# STM32WL31 register map
File version: 1.2
CPU: CM0+ r0p0, little endian, MPU, no FPU, 4 interrupt priority bits
Registers are 32-bit, read-write, reset 0x0 unless marked. A register's access mark holds for its fields unless they carry their own. Offsets are from the block's base; [hi:lo] are bit positions.

## DYNAMIC_REG
Base 0x49000500
0x00 PCKTLEN_CONFIG reset 0x14
  [15:0] PCKTLEN — This bit field has different meanings/usages:
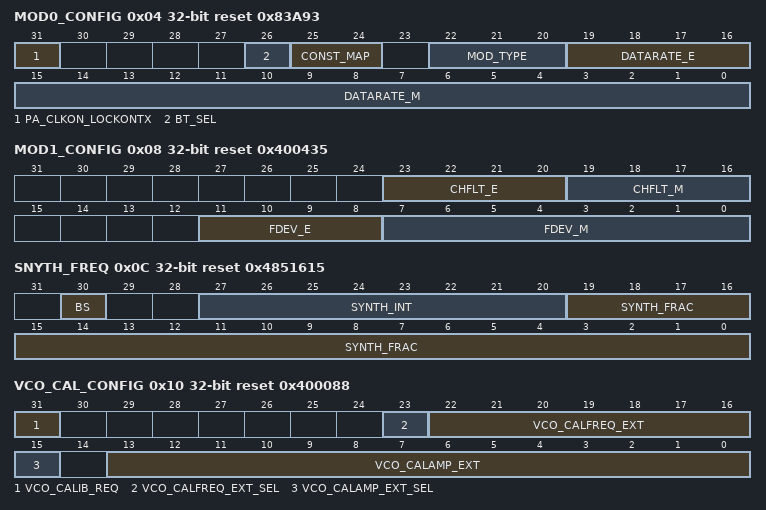
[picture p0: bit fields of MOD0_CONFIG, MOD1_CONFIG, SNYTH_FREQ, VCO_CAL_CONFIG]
0x04 MOD0_CONFIG reset 0x83A93
  [31] PA_CLKON_LOCKONTX — Enable the clock on analog PA in LOCKONTX state
  [26] BT_SEL — Select BT value for GFSK
  [25:24] CONST_MAP — Also known as FOUR_GFSK_CONST_MAP
  [22:20] MOD_TYPE — Select the modulation type
  [19:16] DATARATE_E — The exponent of the specified data rate (default: 38.
  [15:0] DATARATE_M — The mantissa of the specified data rate (default: 38.
0x08 MOD1_CONFIG reset 0x400435
  [23:20] CHFLT_E — Exponent of the channel filter BW (default: 100 kHz)
  [19:16] CHFLT_M — Mantissa of the channel filter BW (default: 100 kHz)
  [11:8] FDEV_E — Exponent of the frequency deviation (default: 28.
  [7:0] FDEV_M — Mantissa of the frequency deviation (default: 28.
0x0C SNYTH_FREQ reset 0x4851615
  [30] BS — Synthesizer band selector, i.
  [27:20] SYNTH_INT — PLL integer divide factor (default: 868 MHz, XTAL: 48 MHz)
  [19:0] SYNTH_FRAC — Fractional part of the PLL fractional divide factor (default: 868 MHz, XTAL: 48 MHz)
0x10 VCO_CAL_CONFIG reset 0x400088
  [31] VCO_CALIB_REQ — Define if the Radio FSM must launch a VCO calibration request after VCO start-up
  [23] VCO_CALFREQ_EXT_SEL — Select the mode to provide an external VCO frequency calibration value through VCO_CALFREQ_EXT bit field
  [22:16] VCO_CALFREQ_EXT — VCO Cbank frequency calibration word.
  [15] VCO_CALAMP_EXT_SEL — Select the mode to provide an external VCO amplitude calibration value through VCO_CALAMP_EXT bit field
  [13:0] VCO_CALAMP_EXT — VCO magnitude calibration word in thermometric code
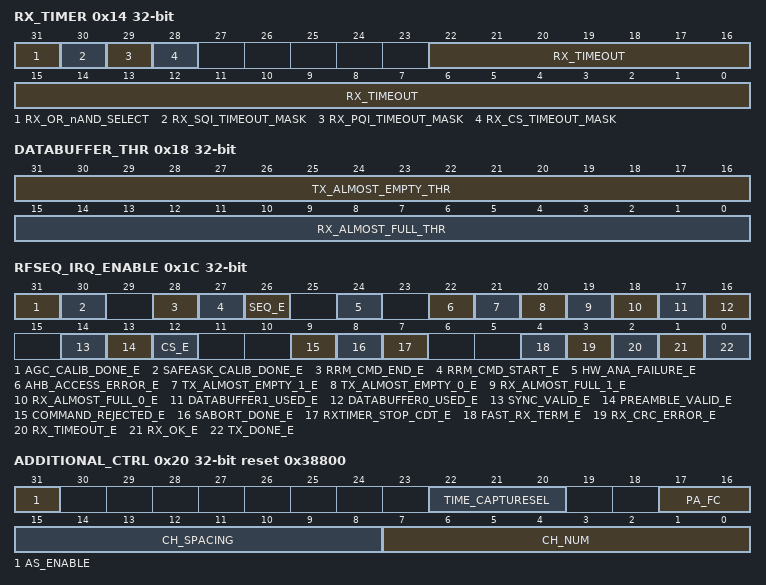
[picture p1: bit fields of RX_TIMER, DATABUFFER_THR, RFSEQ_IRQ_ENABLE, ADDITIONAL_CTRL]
0x14 RX_TIMER
  [31] RX_OR_nAND_SELECT — Select logical OR or logcial AND to apply on CS/PQI/SQI timeout mask
  [30] RX_SQI_TIMEOUT_MASK — - 0: SYNC valid flag does not contribute to timeout disabling
  [29] RX_PQI_TIMEOUT_MASK — - 0: PREAMBLE valid flag does not contribute to timeout disabling
  [28] RX_CS_TIMEOUT_MASK — - 0: CS flag does not contribute to timeout disabling
  [22:0] RX_TIMEOUT — RX timer timeout (relative duration in interpolated absolute time unit)
0x18 DATABUFFER_THR
  [31:16] TX_ALMOST_EMPTY_THR — Almost Empty threshold for TX Data Buffers.
  [15:0] RX_ALMOST_FULL_THR — Almost Full threshold for RX Data Buffers
0x1C RFSEQ_IRQ_ENABLE
  [31] AGC_CALIB_DONE_E — Enable interrupt on AGC_CALIB_DONE_F flag
  [30] SAFEASK_CALIB_DONE_E — Enable interrupt on SAFEASK_CALIB_DONE_F flag
  [28] RRM_CMD_END_E — Enable interrupt on RRM_CMD_END_F flag
  [27] RRM_CMD_START_E — Enable interrupt on RRM_CMD_END_F flag
  [26] SEQ_E — Enable interrupt on SEQ_F flag
  [24] HW_ANA_FAILURE_E — Enable interrupt on HW_ANA_FAILURE_F flag
  [22] AHB_ACCESS_ERROR_E — Enable interrupt on AHB_ACCESS_ERROR_F flag
  [21] TX_ALMOST_EMPTY_1_E — Enable interrupt on TX_ALMOST_EMPTY_1_F flag
  [20] TX_ALMOST_EMPTY_0_E — Enable interrupt on TX_ALMOST_EMPTY_0_F flag
  [19] RX_ALMOST_FULL_1_E — Enable interrupt on RX_ALMOST_FULL_1_F flag
  [18] RX_ALMOST_FULL_0_E — Enable interrupt on RX_ALMOST_FULL_0_F flag
  [17] DATABUFFER1_USED_E — Enable interrupt on DATABUFFER1_USED_F flag
  [16] DATABUFFER0_USED_E — Enable interrupt on DATABUFFER0_USED_F flag
  [14] SYNC_VALID_E — Enable interrupt on SYNC_VALID_F flag
  [13] PREAMBLE_VALID_E — Enable interrupt on PREAMBLE_VALID_F flag
  [12] CS_E — Enable interrupt on CS_F flag
  [9] COMMAND_REJECTED_E — Enable interrupt on COMMAND_REJECTED flag
  [8] SABORT_DONE_E — Enable interrupt on SABORT command treated and done flag
  [7] RXTIMER_STOP_CDT_E — Enable interrupt on RXTIMER_STOP_CDT_F flag
  [4] FAST_RX_TERM_E — Enable interrupt on FAST_RX_TERM_F flag
  [3] RX_CRC_ERROR_E — Enable interrupt on RX_CRC_ERROR_F flag
  [2] RX_TIMEOUT_E — Enable interrupt on RX_TIMEOUT_F flag
  [1] RX_OK_E — Enable interrupt on RX_OK_F flag
  [0] TX_DONE_E — Enable interrupt on TX_DONE_F flag
0x20 ADDITIONAL_CTRL reset 0x38800
  [31] AS_ENABLE — Enable the antenna switching feature.
  [22:20] TIME_CAPTURESEL — Select the trigger event to capture the interpolated absolute time in the TIME_CAPTURE[31:0] register
  [17:16] PA_FC — Power control bandwidth selection according data rate
  [15:8] CH_SPACING ro — Channel spacing.
  [7:0] CH_NUM — Channel number.
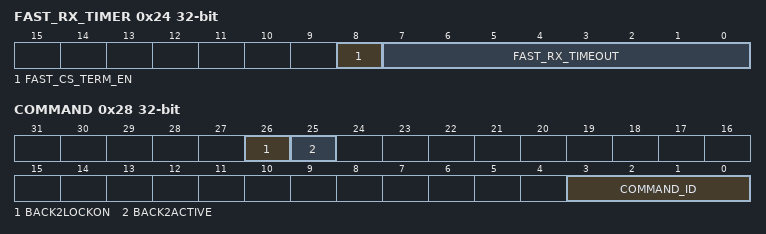
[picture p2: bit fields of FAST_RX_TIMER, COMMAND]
0x24 FAST_RX_TIMER
  [8] FAST_CS_TERM_EN — Enable the Fast RX Termination feature
  [7:0] FAST_RX_TIMEOUT — Fast RX termination timer value (corresponding to the delay to measure the RSSI and to let the HW check CS flag information)
0x28 COMMAND
  [26] BACK2LOCKON — Request to the Radio FSM to stay in LOCKON state when exiting a RX or a TX
  [25] BACK2ACTIVE — Select the default/return state for the Radio FSM to be ACTIVE2
  [3:0] COMMAND_ID — Opcode coresponding to a command:
